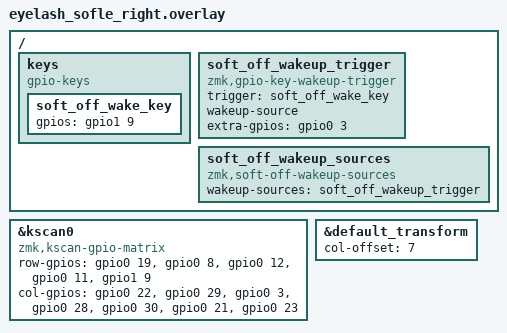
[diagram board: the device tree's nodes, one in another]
/*
*
* Copyright (c) 2021 Darryl deHaan
* SPDX-License-Identifier: MIT
*
*/

#include "eyelash_sofle.dtsi"
#include <behaviors/battery_history_request.dtsi>

&kscan0 {
    compatible = "zmk,kscan-gpio-matrix";
    row-gpios
        = <&gpio0 19 (GPIO_ACTIVE_HIGH | GPIO_PULL_DOWN)>
        , <&gpio0 8 (GPIO_ACTIVE_HIGH | GPIO_PULL_DOWN)>
        , <&gpio0 12 (GPIO_ACTIVE_HIGH | GPIO_PULL_DOWN)>
        , <&gpio0 11 (GPIO_ACTIVE_HIGH | GPIO_PULL_DOWN)>
        , <&gpio1 9 (GPIO_ACTIVE_HIGH | GPIO_PULL_DOWN)>
        ;
    col-gpios
       = <&gpio0 22 GPIO_ACTIVE_HIGH>
        , <&gpio0 29 GPIO_ACTIVE_HIGH>
        , <&gpio0 3 GPIO_ACTIVE_HIGH>
        , <&gpio0 28 GPIO_ACTIVE_HIGH>
        , <&gpio0 30 GPIO_ACTIVE_HIGH>
        , <&gpio0 21 GPIO_ACTIVE_HIGH>
        , <&gpio0 23 GPIO_ACTIVE_HIGH>
        ;
};

/ {
    keys {
        compatible = "gpio-keys";

        soft_off_wake_key: soft_off_wake_key {
            gpios = <&gpio1 9 (GPIO_ACTIVE_HIGH | GPIO_PULL_DOWN)>;
        };
    };

    soft_off_wakeup_trigger: soft_off_wakeup_trigger {
        compatible = "zmk,gpio-key-wakeup-trigger";
        trigger = <&soft_off_wake_key>;
        wakeup-source;
        extra-gpios = <&gpio0 3 GPIO_ACTIVE_HIGH>;
    };

    soft_off_wakeup_sources {
        compatible = "zmk,soft-off-wakeup-sources";
        wakeup-sources = <&soft_off_wakeup_trigger>;
    };
};

&default_transform {
    col-offset = <7>;
};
